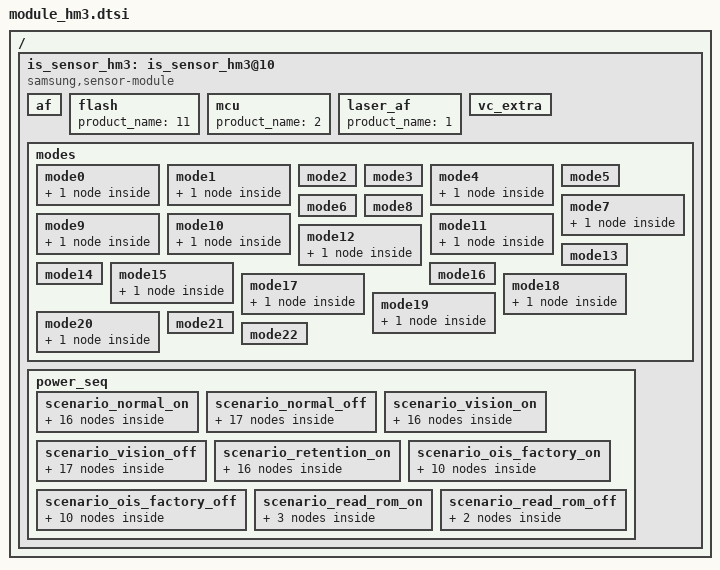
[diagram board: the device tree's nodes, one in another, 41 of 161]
/*
 * SAMSUNG EXYNOSxxxx board camera device tree source
 *
 * Copyright (c) 2019 Samsung Electronics Co., Ltd.
 *		http://www.samsung.com
 *
 * This program is free software; you can redistribute it and/or modify
 * it under the terms of the GNU General Public License version 2 as
 * published by the Free Software Foundation.
 */

#include <dt-bindings/camera/exynos_is_dt.h>

/ {
	fragment@camera {
		target-path = "/";
		__overlay__ {
			is_sensor_hm3: is_sensor_hm3@10 {
				compatible = "samsung,sensor-module";

				/* common */
				sensor_id = <SENSOR_NAME_S5KHM3>;
				active_width = <12000>;
				active_height = <9000>;
				margin_left = <0>;
				margin_right = <0>;
				margin_top = <0>;
				margin_bottom = <0>;
				max_framerate = <240>;
				bitwidth = <10>;
				use_retention_mode = <SENSOR_RETENTION_INACTIVE>;
				sensor_maker = "SLSI";
				sensor_name = "S5KHM3";
				setfile_name = "setfile_hm3.bin";

				status = "okay";

				/* board */
				pinctrl-names = "pin0", "pin1", "pin2", "release";
				pinctrl-0 = <>;
				pinctrl-1 = <&sensor_mclk2_out>;
				pinctrl-2 = <&sensor_mclk2_fn>;
				pinctrl-3 = <>;

				position = <0>;	/* Rear:0. Front:1. Rear_sub:2. Secure:3. */
				id = <0>; /* is_sensor id */
				mclk_ch = <2>;
				mclk_freq = <19200>;
				sensor_i2c_ch = <0>; /* SENSOR_CONTROL_I2C0 */

				/* vendor */
				rom_type = <2>; /* ROM_TYPE_EEPROM */
				rom_id = <0>;
				rom_cal_index = <0>;

				/* peri */
				af {
					product_name = <18>; /* ACTUATOR_NAME_AK737X */
					i2c_ch = <1>; /* SENSOR_CONTROL_I2C1 */
				};

				flash {
					product_name = <11>; /* FLASH_GPIO */
				};

				mcu {
					product_name = <2>; /* INTERNAL */
				};

				laser_af {
					product_name = <1>; /* LASER_AF_NAME_VL53L5 */
				};

				vc_extra {
					/* ex) statX = <stat_type, sensor_mode, max_width, max_height, max_element> */
					stat0 = </* not available */>;									/* VC_BUF_DATA_TYPE_SENSOR_STAT1 */
					stat1 = </*VC_STAT_TYPE_PDP_4_1_PDAF_STAT0*/ 1200 /*VC_SENSOR_MODE_SUPER_PD_4_TAIL*/ 409 1992 1488 2>;	/* VC_BUF_DATA_TYPE_GENERAL_STAT1 */
					stat2 = </* not available */>;									/* VC_BUF_DATA_TYPE_SENSOR_STAT2 */
					stat3 = </*VC_STAT_TYPE_PDP_4_1_PDAF_STAT1*/ 1201 /*VC_SENSOR_MODE_SUPER_PD_4_TAIL*/ 409 1992 1488 2>;	/* VC_BUF_DATA_TYPE_GENERAL_STAT2 */
					stat_vc = <2>; /* STAT out VC after CSIS link */
				};

				/* sensor modes */
				/*
					SENSOR_HM3_12000X9000_10FPS = 0,
					SENSOR_HM3_8000X6000_7FPS = 1,
					SENSOR_HM3_7680X4320_24FPS = 2,
					SENSOR_HM3_7680X4320_30FPS = 3,
					SENSOR_HM3_4000X3000_15FPS_DL_LN4 = 4,
					SENSOR_HM3_4000X3000_15FPS_DL_LN4_R12 = 5,
					SENSOR_HM3_4000X3000_15FPS_RM_ABS = 6,
					SENSOR_HM3_4000X3000_30FPS_3S3A = 7,
					SENSOR_HM3_4000X3000_30FPS_3S3A_LN = 8,
					SENSOR_HM3_4000X3000_30FPS_3S3A_LN_R12 = 9,
					SENSOR_HM3_4000X3000_30FPS_DL = 10,
					SENSOR_HM3_4000X3000_30FPS_DL_LN2 = 11,
					SENSOR_HM3_4000X3000_30FPS_DL_LN2_R12 = 12,
					SENSOR_HM3_4000X3000_30FPS_DL_R12 = 13,
					SENSOR_HM3_4000X3000_30FPS_IDCG_3S3A_R12 = 14,
					SENSOR_HM3_4000X3000_30FPS_IDCG_R12 = 15,
					SENSOR_HM3_4000X3000_60FPS_3S3A = 16,
					SENSOR_HM3_4000X3000_60FPS_3S3A_R12 = 17,
					SENSOR_HM3_4000X3000_60FPS_DL = 18,
					SENSOR_HM3_4000X3000_60FPS_DL_R12 = 19,
					SENSOR_HM3_4000X2252_15FPS_DL_LN4 = 20,
					SENSOR_HM3_4000X2252_15FPS_DL_LN4_R12 = 21,
					SENSOR_HM3_4000X2252_30FPS_3S3A = 22,
					SENSOR_HM3_4000X2252_30FPS_3S3A_LN = 23,
					SENSOR_HM3_4000X2252_30FPS_3S3A_LN_R12 = 24,
					SENSOR_HM3_4000X2252_30FPS_DL = 25,
					SENSOR_HM3_4000X2252_30FPS_DL_LN2 = 26,
					SENSOR_HM3_4000X2252_30FPS_DL_LN2_R12 = 27,
					SENSOR_HM3_4000X2252_30FPS_DL_R12 = 28,
					SENSOR_HM3_4000X2252_30FPS_IDCG_3S3A_R12 = 29,
					SENSOR_HM3_4000X2252_30FPS_IDCG_R12 = 30,
					SENSOR_HM3_4000X2252_30FPS_RM = 31,
					SENSOR_HM3_4000X2252_60FPS_3S3A = 32,
					SENSOR_HM3_4000X2252_60FPS_3S3A_R12 = 33,
					SENSOR_HM3_4000X2252_60FPS_DL = 34,
					SENSOR_HM3_4000X2252_60FPS_DL_R12 = 35,
					SENSOR_HM3_3840X2160_120FPS = 36,
					SENSOR_HM3_3328X1872_120FPS = 37,
					SENSOR_HM3_2800X2100_30FPS_DL = 38,
					SENSOR_HM3_2800X2100_30FPS_DL_R12 = 39,
					SENSOR_HM3_1984X1488_30FPS = 40,
					SENSOR_HM3_1920X1080_240FPS = 41,
					SENSOR_HM3_992X744_120FPS = 42,
				*/
				modes {
					/* common = <width, height, fps, settle, mode, lane, speed, interleave, lrte, pd_mode> */
					/* vcX = <map, hwformat, width, height, hwformat, type, width, height> */
					mode0 { /* SENSOR_HM3_12000X9000_10FPS */
						common = <12000 9000 10 0 0 CSI_DATA_LANES_3 2502 CSI_MODE_VC_DT LRTE_ENABLE PD_MSPD_TAIL>;
						vc0 = </* in */ 0 HW_FORMAT_RAW10 12000 9000	/* out */ HW_FORMAT_RAW10 VC_NOTHING 12000 9000>;
						vc1 = </* in */ 1 HW_FORMAT_UNKNOWN 0 0		/* out */ HW_FORMAT_UNKNOWN VC_NOTHING 0 0>;
						vc2 = </* in */ 2 HW_FORMAT_RAW10_POTF 1992 1488		/* out */ HW_FORMAT_UNKNOWN VC_NOTHING 0 0>;
						vc3 = </* in */ 3 HW_FORMAT_UNKNOWN 0 0		/* out */ HW_FORMAT_UNKNOWN VC_NOTHING 0 0>;
						option { special_mode = <IS_SPECIAL_MODE_REMOSAIC>; };
					};
					mode1 { /* SENSOR_HM3_7680X4320_24FPS */
						common = <7680 4320 24 0 2 CSI_DATA_LANES_3 2502 CSI_MODE_VC_DT LRTE_ENABLE PD_MSPD_TAIL>;
						vc0 = </* in */ 0 HW_FORMAT_RAW10 7680 4320	/* out */ HW_FORMAT_RAW10 VC_NOTHING 7680 4320>;
						vc1 = </* in */ 1 HW_FORMAT_UNKNOWN 0 0		/* out */ HW_FORMAT_UNKNOWN VC_NOTHING 0 0>;
						vc2 = </* in */ 2 HW_FORMAT_RAW10_POTF 1280 720	/* out */ HW_FORMAT_RAW10_POTF VC_TAILPDAF 1280 720>;
						vc3 = </* in */ 3 HW_FORMAT_UNKNOWN 0 0		/* out */ HW_FORMAT_UNKNOWN VC_NOTHING 0 0>;
						option { binning = <1000>; };
					};
					mode2 { /* SENSOR_HM3_4000X3000_30FPS_DL REMOSAIC*/
						common = <4000 3000 30 0 10 CSI_DATA_LANES_3 2502 CSI_MODE_VC_DT LRTE_ENABLE PD_MSPD_TAIL EX_REMOSAIC_CAL>;
						vc0 = </* in */ 0 HW_FORMAT_RAW10 4000 3000	/* out */ HW_FORMAT_RAW10 VC_NOTHING 4000 3000>;
						vc1 = </* in */ 1 HW_FORMAT_UNKNOWN 0 0		/* out */ HW_FORMAT_UNKNOWN VC_NOTHING 0 0>;
						vc2 = </* in */ 2 HW_FORMAT_RAW10_POTF 1992 744	/* out */ HW_FORMAT_RAW10_POTF VC_TAILPDAF 1992 744>;
						vc3 = </* in */ 3 HW_FORMAT_UNKNOWN 0 0		/* out */ HW_FORMAT_UNKNOWN VC_NOTHING 0 0>;
					};
					mode3 { /* SENSOR_HM3_4000X3000_30FPS_DL_R12 */
						common = <4000 3000 30 0 13 CSI_DATA_LANES_3 2502 CSI_MODE_VC_DT LRTE_ENABLE PD_MSPD_TAIL>;
						vc0 = </* in */ 0 HW_FORMAT_RAW12 4000 3000	/* out */ HW_FORMAT_RAW12 VC_NOTHING 4000 3000>;
						vc1 = </* in */ 1 HW_FORMAT_UNKNOWN 0 0		/* out */ HW_FORMAT_UNKNOWN VC_NOTHING 0 0>;
						vc2 = </* in */ 2 HW_FORMAT_RAW10_POTF 1992 744	/* out */ HW_FORMAT_RAW10_POTF VC_TAILPDAF 1992 744>;
						vc3 = </* in */ 3 HW_FORMAT_UNKNOWN 0 0		/* out */ HW_FORMAT_UNKNOWN VC_NOTHING 0 0>;
					};
					mode4 { /* SENSOR_HM3_4000X3000_30FPS_3S3A */
						common = <4000 3000 30 0 7 CSI_DATA_LANES_3 2502 CSI_MODE_VC_DT LRTE_ENABLE PD_MSPD_TAIL>;
						vc0 = </* in */ 0 HW_FORMAT_RAW10 4000 3000	/* out */ HW_FORMAT_RAW10 VC_NOTHING 4000 3000>;
						vc1 = </* in */ 1 HW_FORMAT_UNKNOWN 0 0		/* out */ HW_FORMAT_UNKNOWN VC_NOTHING 0 0>;
						vc2 = </* in */ 2 HW_FORMAT_RAW10_POTF 1992 744	/* out */ HW_FORMAT_RAW10_POTF VC_TAILPDAF 1992 744>;
						vc3 = </* in */ 3 HW_FORMAT_UNKNOWN 0 0		/* out */ HW_FORMAT_UNKNOWN VC_NOTHING 0 0>;
						option { ex_mode_extra = <EX_EXTRA_VIDEO>; };
					};
					mode5 { /* SENSOR_HM3_4000X3000_30FPS_DL */
						common = <4000 3000 30 0 10 CSI_DATA_LANES_3 2502 CSI_MODE_VC_DT LRTE_ENABLE PD_MSPD_TAIL>;
						vc0 = </* in */ 0 HW_FORMAT_RAW10 4000 3000	/* out */ HW_FORMAT_RAW10 VC_NOTHING 4000 3000>;
						vc1 = </* in */ 1 HW_FORMAT_UNKNOWN 0 0		/* out */ HW_FORMAT_UNKNOWN VC_NOTHING 0 0>;
						vc2 = </* in */ 2 HW_FORMAT_RAW10_POTF 1992 744	/* out */ HW_FORMAT_RAW10_POTF VC_TAILPDAF 1992 744>;
						vc3 = </* in */ 3 HW_FORMAT_UNKNOWN 0 0		/* out */ HW_FORMAT_UNKNOWN VC_NOTHING 0 0>;
					};
					mode6 { /* SENSOR_HM3_4000X2252_30FPS_DL_R12 */
						common = <4000 2252 30 0 28 CSI_DATA_LANES_3 2502 CSI_MODE_VC_DT LRTE_ENABLE PD_MSPD_TAIL>;
						vc0 = </* in */ 0 HW_FORMAT_RAW12 4000 2252	/* out */ HW_FORMAT_RAW12 VC_NOTHING 4000 2252>;
						vc1 = </* in */ 1 HW_FORMAT_UNKNOWN 0 0		/* out */ HW_FORMAT_UNKNOWN VC_NOTHING 0 0>;
						vc2 = </* in */ 2 HW_FORMAT_RAW10_POTF 1992 560	/* out */ HW_FORMAT_RAW10_POTF VC_TAILPDAF 1992 560>;
						vc3 = </* in */ 3 HW_FORMAT_UNKNOWN 0 0		/* out */ HW_FORMAT_UNKNOWN VC_NOTHING 0 0>;
					};
					mode7 { /* SENSOR_HM3_4000X2252_30FPS_3S3A */
						common = <4000 2252 30 0 22 CSI_DATA_LANES_3 2502 CSI_MODE_VC_DT LRTE_ENABLE PD_MSPD_TAIL>;
						vc0 = </* in */ 0 HW_FORMAT_RAW10 4000 2252	/* out */ HW_FORMAT_RAW10 VC_NOTHING 4000 2252>;
						vc1 = </* in */ 1 HW_FORMAT_UNKNOWN 0 0		/* out */ HW_FORMAT_UNKNOWN VC_NOTHING 0 0>;
						vc2 = </* in */ 2 HW_FORMAT_RAW10_POTF 1992 560	/* out */ HW_FORMAT_RAW10_POTF VC_TAILPDAF 1992 560>;
						vc3 = </* in */ 3 HW_FORMAT_UNKNOWN 0 0		/* out */ HW_FORMAT_UNKNOWN VC_NOTHING 0 0>;
						option { vvalid_time = <7660>; ex_mode_extra = <EX_EXTRA_VIDEO>; };
					};
					mode8 { /* SENSOR_HM3_4000X2252_30FPS_DL */
						common = <4000 2252 30 0 25 CSI_DATA_LANES_3 2502 CSI_MODE_VC_DT LRTE_ENABLE PD_MSPD_TAIL>;
						vc0 = </* in */ 0 HW_FORMAT_RAW10 4000 2252	/* out */ HW_FORMAT_RAW10 VC_NOTHING 4000 2252>;
						vc1 = </* in */ 1 HW_FORMAT_UNKNOWN 0 0		/* out */ HW_FORMAT_UNKNOWN VC_NOTHING 0 0>;
						vc2 = </* in */ 2 HW_FORMAT_RAW10_POTF 1992 560	/* out */ HW_FORMAT_RAW10_POTF VC_TAILPDAF 1992 560>;
						vc3 = </* in */ 3 HW_FORMAT_UNKNOWN 0 0		/* out */ HW_FORMAT_UNKNOWN VC_NOTHING 0 0>;
					};
					mode9 { /* SENSOR_HM3_4000X3000_60FPS_3S3A */
						common = <4000 3000 60 0 16 CSI_DATA_LANES_3 2502 CSI_MODE_VC_DT LRTE_ENABLE PD_MSPD_TAIL>;
						vc0 = </* in */ 0 HW_FORMAT_RAW10 4000 3000	/* out */ HW_FORMAT_RAW10 VC_NOTHING 4000 3000>;
						vc1 = </* in */ 1 HW_FORMAT_UNKNOWN 0 0		/* out */ HW_FORMAT_UNKNOWN VC_NOTHING 0 0>;
						vc2 = </* in */ 2 HW_FORMAT_RAW10_POTF 1992 744	/* out */ HW_FORMAT_RAW10_POTF VC_TAILPDAF 1992 744>;
						vc3 = </* in */ 3 HW_FORMAT_UNKNOWN 0 0		/* out */ HW_FORMAT_UNKNOWN VC_NOTHING 0 0>;
						option { ex_mode_extra = <EX_EXTRA_VIDEO>; };
					};
					mode10 { /* SENSOR_HM3_4000X3000_60FPS_3S3A_R12 */
						common = <4000 3000 60 0 17 CSI_DATA_LANES_3 2502 CSI_MODE_VC_DT LRTE_ENABLE PD_MSPD_TAIL>;
						vc0 = </* in */ 0 HW_FORMAT_RAW12 4000 3000	/* out */ HW_FORMAT_RAW12 VC_NOTHING 4000 3000>;
						vc1 = </* in */ 1 HW_FORMAT_UNKNOWN 0 0		/* out */ HW_FORMAT_UNKNOWN VC_NOTHING 0 0>;
						vc2 = </* in */ 2 HW_FORMAT_RAW10_POTF 1992 744	/* out */ HW_FORMAT_RAW10_POTF VC_TAILPDAF 1992 744>;
						vc3 = </* in */ 3 HW_FORMAT_UNKNOWN 0 0		/* out */ HW_FORMAT_UNKNOWN VC_NOTHING 0 0>;
						option { ex_mode_extra = <EX_EXTRA_VIDEO>; };
					};
					mode11 { /* SENSOR_HM3_4000X2252_60FPS_3S3A */
						common = <4000 2252 60 0 32 CSI_DATA_LANES_3 2502 CSI_MODE_VC_DT LRTE_ENABLE PD_MSPD_TAIL>;
						vc0 = </* in */ 0 HW_FORMAT_RAW10 4000 2252	/* out */ HW_FORMAT_RAW10 VC_NOTHING 4000 2252>;
						vc1 = </* in */ 1 HW_FORMAT_UNKNOWN 0 0		/* out */ HW_FORMAT_UNKNOWN VC_NOTHING 0 0>;
						vc2 = </* in */ 2 HW_FORMAT_RAW10_POTF 1992 560	/* out */ HW_FORMAT_RAW10_POTF VC_TAILPDAF 1992 560>;
						vc3 = </* in */ 3 HW_FORMAT_UNKNOWN 0 0		/* out */ HW_FORMAT_UNKNOWN VC_NOTHING 0 0>;
						option { vvalid_time = <7660>; };
					};
					mode12 { /* SENSOR_HM3_4000X2252_60FPS_3S3A_R12 */
						common = <4000 2252 60 0 33 CSI_DATA_LANES_3 2502 CSI_MODE_VC_DT LRTE_ENABLE PD_MSPD_TAIL>;
						vc0 = </* in */ 0 HW_FORMAT_RAW12 4000 2252	/* out */ HW_FORMAT_RAW12 VC_NOTHING 4000 2252>;
						vc1 = </* in */ 1 HW_FORMAT_UNKNOWN 0 0		/* out */ HW_FORMAT_UNKNOWN VC_NOTHING 0 0>;
						vc2 = </* in */ 2 HW_FORMAT_RAW10_POTF 1992 560	/* out */ HW_FORMAT_RAW10_POTF VC_TAILPDAF 1992 560>;
						vc3 = </* in */ 3 HW_FORMAT_UNKNOWN 0 0		/* out */ HW_FORMAT_UNKNOWN VC_NOTHING 0 0>;
						option { vvalid_time = <7660>; ex_mode_extra = <EX_EXTRA_VIDEO>; };
					};
					mode13 { /* SENSOR_HM3_3840X2160_120FPS */
						common = <3840 2160 120 0 36 CSI_DATA_LANES_3 2502 CSI_MODE_VC_DT LRTE_ENABLE PD_MSPD_TAIL>;
						vc0 = </* in */ 0 HW_FORMAT_RAW10 3840 2160	/* out */ HW_FORMAT_RAW10 VC_NOTHING 3840 2160>;
						vc1 = </* in */ 1 HW_FORMAT_UNKNOWN 0 0		/* out */ HW_FORMAT_UNKNOWN VC_NOTHING 0 0>;
						vc2 = </* in */ 2 HW_FORMAT_RAW10_POTF 1920 540	/* out */ HW_FORMAT_RAW10_POTF VC_TAILPDAF 1920 540>;
						vc3 = </* in */ 3 HW_FORMAT_UNKNOWN 0 0		/* out */ HW_FORMAT_UNKNOWN VC_NOTHING 0 0>;
					};
					mode14 { /* SENSOR_HM3_3328X1872_120FPS */
						common = <3328 1872 120 0 37 CSI_DATA_LANES_3 2502 CSI_MODE_VC_DT LRTE_ENABLE PD_MSPD_TAIL>;
						vc0 = </* in */ 0 HW_FORMAT_RAW10 3328 1872	/* out */ HW_FORMAT_RAW10 VC_NOTHING 3328 1872>;
						vc1 = </* in */ 1 HW_FORMAT_UNKNOWN 0 0		/* out */ HW_FORMAT_UNKNOWN VC_NOTHING 0 0>;
						vc2 = </* in */ 2 HW_FORMAT_RAW10_POTF 1664 468	/* out */ HW_FORMAT_RAW10_POTF VC_TAILPDAF 1664 468>;
						vc3 = </* in */ 3 HW_FORMAT_UNKNOWN 0 0		/* out */ HW_FORMAT_UNKNOWN VC_NOTHING 0 0>;
					};
					mode15 { /* SENSOR_HM3_1984X1488_30FPS */
						common = <1984 1488 30 0 40 CSI_DATA_LANES_3 2502 CSI_MODE_VC_DT LRTE_ENABLE PD_MSPD_TAIL>;
						vc0 = </* in */ 0 HW_FORMAT_RAW10 1984 1488	/* out */ HW_FORMAT_RAW10 VC_NOTHING 1984 1488>;
						vc1 = </* in */ 1 HW_FORMAT_UNKNOWN 0 0		/* out */ HW_FORMAT_UNKNOWN VC_NOTHING 0 0>;
						vc2 = </* in */ 2 HW_FORMAT_RAW10_POTF 992 372	/* out */ HW_FORMAT_RAW10_POTF VC_TAILPDAF 992 372>;
						vc3 = </* in */ 3 HW_FORMAT_UNKNOWN 0 0		/* out */ HW_FORMAT_UNKNOWN VC_NOTHING 0 0>;
						option { vvalid_time = <5090>; };
					};
					mode16 { /* SENSOR_HM3_1920X1080_240FPS */
						common = <1920 1080 240 0 41 CSI_DATA_LANES_3 2502 CSI_MODE_VC_DT LRTE_ENABLE PD_MSPD_TAIL>;
						vc0 = </* in */ 0 HW_FORMAT_RAW10 1920 1080	/* out */ HW_FORMAT_RAW10 VC_NOTHING 1920 1080>;
						vc1 = </* in */ 1 HW_FORMAT_UNKNOWN 0 0		/* out */ HW_FORMAT_UNKNOWN VC_NOTHING 0 0>;
						vc2 = </* in */ 2 HW_FORMAT_RAW10_POTF 960 270	/* out */ HW_FORMAT_RAW10_POTF VC_TAILPDAF 960 270>;
						vc3 = </* in */ 3 HW_FORMAT_UNKNOWN 0 0		/* out */ HW_FORMAT_UNKNOWN VC_NOTHING 0 0>;
					};
					mode17 { /* SENSOR_HM3_992X744_120FPS */
						common = <992 744 120 0 42 CSI_DATA_LANES_3 2502 CSI_MODE_VC_DT LRTE_ENABLE PD_NONE>;
						vc0 = </* in */ 0 HW_FORMAT_RAW10 992 744	/* out */ HW_FORMAT_RAW10 VC_NOTHING 992 744>;
						vc1 = </* in */ 1 HW_FORMAT_UNKNOWN 0 0		/* out */ HW_FORMAT_UNKNOWN VC_NOTHING 0 0>;
						vc2 = </* in */ 2 HW_FORMAT_UNKNOWN 0 0		/* out */ HW_FORMAT_UNKNOWN VC_NOTHING 0 0>;
						vc3 = </* in */ 3 HW_FORMAT_UNKNOWN 0 0		/* out */ HW_FORMAT_UNKNOWN VC_NOTHING 0 0>;
						option { binning = <6000>; special_mode = <IS_SPECIAL_MODE_FASTAE>; };
					};
					mode18 { /* SENSOR_HM3_12000X9000_10FPS */
						common = <12000 9000 10 0 0 CSI_DATA_LANES_3 2502 CSI_MODE_VC_DT LRTE_ENABLE PD_MSPD_TAIL EX_AI_REMOSAIC>;
						vc0 = </* in */ 0 HW_FORMAT_RAW10 12000 9000	/* out */ HW_FORMAT_RAW10 VC_NOTHING 12000 9000>;
						vc1 = </* in */ 1 HW_FORMAT_UNKNOWN 0 0		/* out */ HW_FORMAT_UNKNOWN VC_NOTHING 0 0>;
						vc2 = </* in */ 2 HW_FORMAT_RAW10_POTF 1992 1488		/* out */ HW_FORMAT_UNKNOWN VC_NOTHING 0 0>;
						vc3 = </* in */ 3 HW_FORMAT_UNKNOWN 0 0		/* out */ HW_FORMAT_UNKNOWN VC_NOTHING 0 0>;
						option { special_mode = <IS_SPECIAL_MODE_REMOSAIC>; };
					};
					mode19 { /* SENSOR_HM3_4000X3000_30FPS_DL EX_AEB*/
						common = <4000 3000 30 0 10 CSI_DATA_LANES_3 2502 CSI_MODE_VC_DT LRTE_ENABLE PD_MSPD_TAIL EX_AEB>;
						vc0 = </* in */ 0 HW_FORMAT_RAW10 4000 3000	/* out */ HW_FORMAT_RAW10 VC_NOTHING 4000 3000>;
						vc1 = </* in */ 1 HW_FORMAT_RAW10 4000 3000	/* out */ HW_FORMAT_RAW10 VC_NOTHING 4000 3000>;
						vc2 = </* in */ 2 HW_FORMAT_RAW10_POTF 1992 744	/* out */ HW_FORMAT_RAW10_POTF VC_TAILPDAF 1992 744>;
						vc3 = </* in */ 3 HW_FORMAT_RAW10_POTF 1992 744	/* out */ HW_FORMAT_UNKNOWN VC_NOTHING 0 0>;
						option { max_fps = <60>; };
					};
					mode20 { /* SENSOR_HM3_4000X3000_30FPS_DL_R12 EX_AEB*/
						common = <4000 3000 30 0 13 CSI_DATA_LANES_3 2502 CSI_MODE_VC_DT LRTE_ENABLE PD_MSPD_TAIL EX_AEB>;
						vc0 = </* in */ 0 HW_FORMAT_RAW12 4000 3000	/* out */ HW_FORMAT_RAW12 VC_NOTHING 4000 3000>;
						vc1 = </* in */ 1 HW_FORMAT_RAW12 4000 3000	/* out */ HW_FORMAT_RAW12 VC_NOTHING 4000 3000>;
						vc2 = </* in */ 2 HW_FORMAT_RAW10_POTF 1992 744	/* out */ HW_FORMAT_RAW10_POTF VC_TAILPDAF 1992 744>;
						vc3 = </* in */ 3 HW_FORMAT_RAW10_POTF 1992 744	/* out */ HW_FORMAT_UNKNOWN VC_NOTHING 0 0>;
						option { max_fps = <60>; };
					};
					mode21 { /* SENSOR_HM3_2800X2100_30FPS_DL */
						common = <2800 2100 30 0 38 CSI_DATA_LANES_3 2502 CSI_MODE_VC_DT LRTE_ENABLE PD_MSPD_TAIL>;
						vc0 = </* in */ 0 HW_FORMAT_RAW10 2800 2100	/* out */ HW_FORMAT_RAW10 VC_NOTHING 2800 2100>;
						vc1 = </* in */ 1 HW_FORMAT_UNKNOWN 0 0		/* out */ HW_FORMAT_UNKNOWN VC_NOTHING 0 0>;
						vc2 = </* in */ 2 HW_FORMAT_RAW10_POTF 1400 522	/* out */ HW_FORMAT_RAW10_POTF VC_TAILPDAF 1400 522>;
						vc3 = </* in */ 3 HW_FORMAT_UNKNOWN 0 0		/* out */ HW_FORMAT_UNKNOWN VC_NOTHING 0 0>;
					};
					mode22 { /* SENSOR_HM3_2800X2100_30FPS_DL_R12 */
						common = <2800 2100 30 0 39 CSI_DATA_LANES_3 2502 CSI_MODE_VC_DT LRTE_ENABLE PD_MSPD_TAIL>;
						vc0 = </* in */ 0 HW_FORMAT_RAW12 2800 2100	/* out */ HW_FORMAT_RAW12 VC_NOTHING 2800 2100>;
						vc1 = </* in */ 1 HW_FORMAT_UNKNOWN 0 0		/* out */ HW_FORMAT_UNKNOWN VC_NOTHING 0 0>;
						vc2 = </* in */ 2 HW_FORMAT_RAW10_POTF 1400 522	/* out */ HW_FORMAT_RAW10_POTF VC_TAILPDAF 1400 522>;
						vc3 = </* in */ 3 HW_FORMAT_UNKNOWN 0 0		/* out */ HW_FORMAT_UNKNOWN VC_NOTHING 0 0>;
					};
				};


				power_seq {
					use = <1>;
					gpio_mclk = <&gpg1 2 0x1>;
					scenario_normal_on {
						sensor_scenario = <SENSOR_SCENARIO_NORMAL>;
						gpio_scenario = <GPIO_SCENARIO_ON>;

						/* A start node number should be over the 10 for reserved number 0~9. */
						/* pname = "name"; pin = <act value delay voltage>; gpio = <gpx# # 0x1>; */
						10 { pname = "sen_rst low"; pin = <PIN_OUTPUT 0 0>; gpio = <&gpc0 0 0x1>; };
						15 { pname = "VDDOIS_3.3V_CAM"; pin = <PIN_REGULATOR 1 0>; share = <SRT_ACQUIRE SHARED_PIN3 1>; };
						16 { pname = "VDDOIS_3.3V_SUB"; pin = <PIN_REGULATOR 1 0>; share = <SRT_ACQUIRE SHARED_PIN9 1>; };
						20 { pname = "VDDIO_1.8V_CAM"; pin = <PIN_REGULATOR 1 0>; share = <SRT_ACQUIRE SHARED_PIN2 1>; };
						25 { pname = "VDDIO_1.8V_COMMON"; pin = <PIN_REGULATOR 1 0>; share = <SRT_ACQUIRE SHARED_PIN0 1>; };
						30 { pname = "VDDA_2.8V_CAM"; pin = <PIN_REGULATOR 1 0>; };
						40 { pname = "VDDPHY_1.05V_CAM"; pin = <PIN_REGULATOR 1 0>; };
						50 { pname = "VDDD_1.05V_CAM"; pin = <PIN_REGULATOR 1 1>; };
						60 { pname = "VDDAF_3.3V_CAM"; pin = <PIN_REGULATOR 1 1>; share = <SRT_ACQUIRE SHARED_PIN4 1>; actuator_i2c_delay = <10000>; };
						75 { pname = "VDDOIS_1.8V_SUB"; pin = <PIN_REGULATOR 1 10>; share = <SRT_ACQUIRE SHARED_PIN6 1>; };
						80 { pname = "VDDA_AF_OIS_3.0V_SUB2"; pin = <PIN_REGULATOR 1 10>; share = <SRT_ACQUIRE SHARED_PIN8 1>; };
						85 { pname = "VDDAFOIS_3.0V_SUB2"; pin = <PIN_REGULATOR 1 0>; share = <SRT_ACQUIRE SHARED_PIN7 1>; };
						90 { pname = "on_i2c"; pin = <PIN_I2C 1 0>; };
						100 { pname = "pin"; pin = <PIN_FUNCTION 2 0>; };
						110 { pname = "MCLK"; pin = <PIN_MCLK 1 1500>; };
						120 { pname = "sen_rst high"; pin = <PIN_OUTPUT 1 8200>; gpio = <&gpc0 0 0x1>; };
					};

					scenario_normal_off {
						sensor_scenario = <SENSOR_SCENARIO_NORMAL>;
						gpio_scenario = <GPIO_SCENARIO_OFF>;

						/* A start node number should be over the 10 for reserved number 0~9. */
						/* pname = "name"; pin = <act value delay voltage>; gpio = <gpx# # 0x1>; */
						5 { pname = "sen_rst low"; pin = <PIN_OUTPUT 0 10>; gpio = <&gpc0 0 0x1>; };
						10 { pname = "VDDAF_3.3V_CAM"; pin = <PIN_REGULATOR 0 10>; share = <SRT_RELEASE SHARED_PIN4 0>; };
						16 { pname = "VDDAFOIS_3.0V_SUB2"; pin = <PIN_REGULATOR 0 10>; share = <SRT_RELEASE SHARED_PIN7 0>; };
						17 { pname = "VDDA_AF_OIS_3.0V_SUB2"; pin = <PIN_REGULATOR 0 10>; share = <SRT_RELEASE SHARED_PIN8 0>; };
						18 { pname = "VDDOIS_1.8V_SUB"; pin = <PIN_REGULATOR 0 0>; share = <SRT_RELEASE SHARED_PIN6 0>; };
						20 { pname = "VDDPHY_1.05V_CAM"; pin = <PIN_REGULATOR 0 0>; };
						30 { pname = "VDDD_1.05V_CAM"; pin = <PIN_REGULATOR 0 10>; };
						40 { pname = "VDDA_2.8V_CAM"; pin = <PIN_REGULATOR 0 0>; };
						60 { pname = "MCLK"; pin = <PIN_MCLK 0 0>; };
						70 { pname = "pin"; pin = <PIN_FUNCTION 0 0>; };
						80 { pname = "pin"; pin = <PIN_FUNCTION 1 0>; };
						90 { pname = "pin"; pin = <PIN_FUNCTION 0 0>; };
						110 { pname = "off_i2c"; pin = <PIN_I2C 0 0>; };
						130 { pname = "VDDIO_1.8V_CAM"; pin = <PIN_REGULATOR 0 10>; share = <SRT_RELEASE SHARED_PIN2 0>; };
						133 { pname = "VDDIO_1.8V_COMMON"; pin = <PIN_REGULATOR 0 0>; share = <SRT_RELEASE SHARED_PIN0 0>; };
						137 { pname = "VDDOIS_3.3V_CAM"; pin = <PIN_REGULATOR 0 0>; share = <SRT_RELEASE SHARED_PIN3 0>; };
						138 { pname = "VDDOIS_3.3V_SUB"; pin = <PIN_REGULATOR 0 0>; share = <SRT_RELEASE SHARED_PIN9 0>; };
					};

					scenario_vision_on {
						sensor_scenario = <SENSOR_SCENARIO_VISION>;
						gpio_scenario = <GPIO_SCENARIO_ON>;

						10 { pname = "sen_rst low"; pin = <PIN_OUTPUT 0 0>; gpio = <&gpc0 0 0x1>; };
						15 { pname = "VDDOIS_3.3V_CAM"; pin = <PIN_REGULATOR 1 0>; share = <SRT_ACQUIRE SHARED_PIN3 1>; };
						16 { pname = "VDDOIS_3.3V_SUB"; pin = <PIN_REGULATOR 1 0>; share = <SRT_ACQUIRE SHARED_PIN9 1>; };
						20 { pname = "VDDIO_1.8V_CAM"; pin = <PIN_REGULATOR 1 0>; share = <SRT_ACQUIRE SHARED_PIN2 1>; };
						25 { pname = "VDDIO_1.8V_COMMON"; pin = <PIN_REGULATOR 1 0>; share = <SRT_ACQUIRE SHARED_PIN0 1>; };
						30 { pname = "VDDA_2.8V_CAM"; pin = <PIN_REGULATOR 1 0>; };
						40 { pname = "VDDPHY_1.05V_CAM"; pin = <PIN_REGULATOR 1 0>; };
						50 { pname = "VDDD_1.05V_CAM"; pin = <PIN_REGULATOR 1 1>; };
						60 { pname = "VDDAF_3.3V_CAM"; pin = <PIN_REGULATOR 1 1>; share = <SRT_ACQUIRE SHARED_PIN4 1>; actuator_i2c_delay = <10000>; };
						75 { pname = "VDDOIS_1.8V_SUB"; pin = <PIN_REGULATOR 1 0>; share = <SRT_ACQUIRE SHARED_PIN6 1>; };
						80 { pname = "VDDAFOIS_3.0V_SUB2"; pin = <PIN_REGULATOR 1 0>; share = <SRT_ACQUIRE SHARED_PIN7 1>; };
						85 { pname = "VDDA_AF_OIS_3.0V_SUB2"; pin = <PIN_REGULATOR 1 0>; share = <SRT_ACQUIRE SHARED_PIN8 1>; };
						90 { pname = "on_i2c"; pin = <PIN_I2C 1 0>; };
						100 { pname = "pin"; pin = <PIN_FUNCTION 2 0>; };
						110 { pname = "MCLK"; pin = <PIN_MCLK 1 1500>; };
						120 { pname = "sen_rst high"; pin = <PIN_OUTPUT 1 8200>; gpio = <&gpc0 0 0x1>; };
					};

					scenario_vision_off {
						sensor_scenario = <SENSOR_SCENARIO_VISION>;
						gpio_scenario = <GPIO_SCENARIO_OFF>;

						5 { pname = "sen_rst low"; pin = <PIN_OUTPUT 0 10>; gpio = <&gpc0 0 0x1>; };
						10 { pname = "VDDAF_3.3V_CAM"; pin = <PIN_REGULATOR 0 10>; share = <SRT_RELEASE SHARED_PIN4 0>; };
						16 { pname = "VDDAFOIS_3.0V_SUB2"; pin = <PIN_REGULATOR 0 0>; share = <SRT_RELEASE SHARED_PIN7 0>; };
						17 { pname = "VDDOIS_1.8V_SUB"; pin = <PIN_REGULATOR 0 0>; share = <SRT_RELEASE SHARED_PIN6 0>; };
						18 { pname = "VDDA_AF_OIS_3.0V_SUB2"; pin = <PIN_REGULATOR 0 0>; share = <SRT_RELEASE SHARED_PIN8 0>; };
						20 { pname = "VDDPHY_1.05V_CAM"; pin = <PIN_REGULATOR 0 0>; };
						30 { pname = "VDDD_1.05V_CAM"; pin = <PIN_REGULATOR 0 10>; };
						40 { pname = "VDDA_2.8V_CAM"; pin = <PIN_REGULATOR 0 0>; };
						60 { pname = "MCLK"; pin = <PIN_MCLK 0 0>; };
						70 { pname = "pin"; pin = <PIN_FUNCTION 0 0>; };
						80 { pname = "pin"; pin = <PIN_FUNCTION 1 0>; };
						90 { pname = "pin"; pin = <PIN_FUNCTION 0 0>; };
						110 { pname = "off_i2c"; pin = <PIN_I2C 0 0>; };
						130 { pname = "VDDIO_1.8V_CAM"; pin = <PIN_REGULATOR 0 10>; share = <SRT_RELEASE SHARED_PIN2 0>; };
						133 { pname = "VDDIO_1.8V_COMMON"; pin = <PIN_REGULATOR 0 0>; share = <SRT_RELEASE SHARED_PIN0 0>; };
						137 { pname = "VDDOIS_3.3V_CAM"; pin = <PIN_REGULATOR 0 0>; share = <SRT_RELEASE SHARED_PIN3 0>; };
						138 { pname = "VDDOIS_3.3V_SUB"; pin = <PIN_REGULATOR 0 0>; share = <SRT_RELEASE SHARED_PIN9 0>; };
					};

					scenario_retention_on {
						sensor_scenario = <SENSOR_SCENARIO_NORMAL>;
						gpio_scenario = <GPIO_SCENARIO_SENSOR_RETENTION_ON>;

						/* A start node number should be over the 10 for reserved number 0~9. */
						/* pname = "name"; pin = <act value delay voltage>; gpio = <gpx# # 0x1>; */
						5 { pname = "(retention) sen_rst low"; pin = <PIN_OUTPUT 0 10>; gpio = <&gpc0 0 0x1>; };
						10 { pname = "MCLK"; pin = <PIN_MCLK 0 0>; };
						20 { pname = "pin"; pin = <PIN_FUNCTION 0 0>; };
						30 { pname = "pin"; pin = <PIN_FUNCTION 1 0>; };
						40 { pname = "pin"; pin = <PIN_FUNCTION 0 0>; };
						50 { pname = "VDDAF_3.3V_CAM"; pin = <PIN_REGULATOR 0 10>; share = <SRT_RELEASE SHARED_PIN4 0>; };
						56 { pname = "VDDAFOIS_3.0V_SUB2"; pin = <PIN_REGULATOR 0 10>; share = <SRT_RELEASE SHARED_PIN7 0>; };
						57 { pname = "VDDA_AF_OIS_3.0V_SUB2"; pin = <PIN_REGULATOR 0 10>; share = <SRT_RELEASE SHARED_PIN8 0>; };
						58 { pname = "VDDOIS_1.8V_SUB"; pin = <PIN_REGULATOR 0 0>; share = <SRT_RELEASE SHARED_PIN6 0>; };
						60 { pname = "VDDPHY_1.05V_CAM"; pin = <PIN_REGULATOR 0 0>; };
						70 { pname = "VDDD_1.05V_CAM"; pin = <PIN_REGULATOR 0 10>; };
						80 { pname = "VDDA_2.8V_CAM"; pin = <PIN_REGULATOR 0 0>; };
						110 { pname = "off_i2c"; pin = <PIN_I2C 0 0>; };
						133 { pname = "VDDIO_1.8V_COMMON"; pin = <PIN_REGULATOR 0 0>; share = <SRT_RELEASE SHARED_PIN0 0>; };
						137 { pname = "VDDOIS_3.3V_CAM"; pin = <PIN_REGULATOR 0 0>; share = <SRT_RELEASE SHARED_PIN3 0>; };
						138 { pname = "VDDOIS_3.3V_SUB"; pin = <PIN_REGULATOR 0 0>; share = <SRT_RELEASE SHARED_PIN9 0>; };
					};

					scenario_ois_factory_on {
						sensor_scenario = <SENSOR_SCENARIO_OIS_FACTORY>;
						gpio_scenario = <GPIO_SCENARIO_ON>;

						/* A start node number should be over the 10 for reserved number 0~9. */
						/* pname = "name"; pin = <act value delay voltage>; gpio = <gpx# # 0x1>; */
						10 { pname = "VDDIO_1.8V_CAM"; pin = <PIN_REGULATOR 1 0>; };
						20 { pname = "VDDIO_1.8V_COMMON"; pin = <PIN_REGULATOR 1 0>; };
						30 { pname = "VDDOIS_3.3V_CAM"; pin = <PIN_REGULATOR 1 0>; };
						40 { pname = "VDDOIS_3.3V_SUB"; pin = <PIN_REGULATOR 1 100>; };
						50 { pname = "VDDAF_3.3V_CAM"; pin = <PIN_REGULATOR 1 0>; };
						60 { pname = "VDDAF_3.3V_SUB"; pin = <PIN_REGULATOR 1 100>; };
						70 { pname = "VDDOIS_1.8V_SUB"; pin = <PIN_REGULATOR 1 10>; };
						80 { pname = "VDDA_AF_OIS_3.0V_SUB2"; pin = <PIN_REGULATOR 1 10>; };
						90 { pname = "VDDAFOIS_3.0V_SUB2"; pin = <PIN_REGULATOR 1 0>; };
						100 { pname = "on_i2c"; pin = <PIN_I2C 1 10>; };
					};

					scenario_ois_factory_off {
						sensor_scenario = <SENSOR_SCENARIO_OIS_FACTORY>;
						gpio_scenario = <GPIO_SCENARIO_OFF>;

						/* A start node number should be over the 10 for reserved number 0~9. */
						/* pname = "name"; pin = <act value delay voltage>; gpio = <gpx# # 0x1>; */
						10 { pname = "off_i2c"; pin = <PIN_I2C 0 0>; };
						20 { pname = "VDDAF_3.3V_CAM"; pin = <PIN_REGULATOR 0 0>; };
						30 { pname = "VDDAF_3.3V_SUB"; pin = <PIN_REGULATOR 0 0>; };
						40 { pname = "VDDAFOIS_3.0V_SUB2"; pin = <PIN_REGULATOR 0 10>; };
						50 { pname = "VDDA_AF_OIS_3.0V_SUB2"; pin = <PIN_REGULATOR 0 10>; };
						60 { pname = "VDDOIS_1.8V_SUB"; pin = <PIN_REGULATOR 0 0>; };
						70 { pname = "VDDIO_1.8V_CAM"; pin = <PIN_REGULATOR 0 10>; };
						80 { pname = "VDDIO_1.8V_COMMON"; pin = <PIN_REGULATOR 0 0>; };
						90 { pname = "VDDOIS_3.3V_CAM"; pin = <PIN_REGULATOR 0 0>; };
						100 { pname = "VDDOIS_3.3V_SUB"; pin = <PIN_REGULATOR 0 0>; };
					};

					scenario_read_rom_on {
						sensor_scenario = <SENSOR_SCENARIO_READ_ROM>;
						gpio_scenario = <GPIO_SCENARIO_ON>;

						/* A start node number should be over the 10 for reserved number 0~9. */
						/* pname = "name"; pin = <act value delay voltage>; gpio = <gpx# # 0x1>; */
						5 { pname = "delay"; pin = <PIN_NONE 0 20000>; };
						10 { pname = "VDDIO_1.8V_CAM"; pin = <PIN_REGULATOR 1 5000>; };
						20 { pname = "on_i2c"; pin = <PIN_I2C 1 0>; };
					};

					scenario_read_rom_off {
						sensor_scenario = <SENSOR_SCENARIO_READ_ROM>;
						gpio_scenario = <GPIO_SCENARIO_OFF>;

						/* A start node number should be over the 10 for reserved number 0~9. */
						/* pname = "name"; pin = <act value delay voltage>; gpio = <gpx# # 0x1>; */
						10 { pname = "off_i2c"; pin = <PIN_I2C 0 0>; };
						20 { pname = "VDDIO_1.8V_CAM"; pin = <PIN_REGULATOR 0 10>; };
					};
				};
			};
		}; /* end of __overlay__ */
	}; /* end of fragment */
}; /* end of root */
